AUTOSAR XML (schema 00046)
package /ComponentTypes
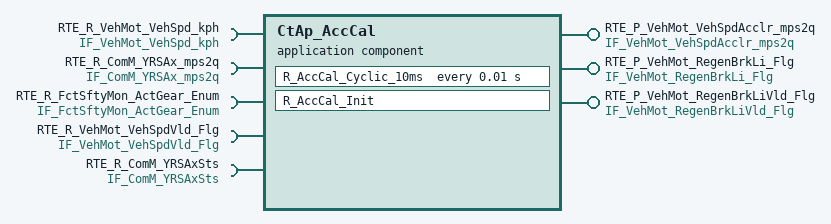
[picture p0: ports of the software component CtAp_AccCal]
  application sw component type CtAp_AccCal
    provide port RTE_P_VehMot_VehSpdAcclr_mps2q: nonqueued-sender-com-spec{data-element=tec_VehMot_VehSpdAcclr_mps2q, init-value=0}, provided-interface=IF_VehMot_VehSpdAcclr_mps2q
    provide port RTE_P_VehMot_RegenBrkLi_Flg: nonqueued-sender-com-spec{data-element=tec_VehMot_RegenBrkLi_Flg, init-value=0}, provided-interface=IF_VehMot_RegenBrkLi_Flg
    require port RTE_R_VehMot_VehSpd_kph: nonqueued-receiver-com-spec{data-element=tec_VehMot_VehSpd_kph, filter=data-filter-type=ALWAYS, init-value=0}, required-interface=IF_VehMot_VehSpd_kph
    require port RTE_R_ComM_YRSAx_mps2q: nonqueued-receiver-com-spec{data-element=tec_ComM_YRSAx_mps2q, filter=data-filter-type=ALWAYS, init-value=0}, required-interface=IF_ComM_YRSAx_mps2q
    provide port RTE_P_VehMot_RegenBrkLiVld_Flg: nonqueued-sender-com-spec{data-element=tec_VehMot_RegenBrkLiVld_Flg, init-value=0}, provided-interface=IF_VehMot_RegenBrkLiVld_Flg
    require port RTE_R_FctSftyMon_ActGear_Enum: nonqueued-receiver-com-spec{data-element=tec_FctSftyMon_ActGear_Enum, filter=data-filter-type=ALWAYS, init-value=0}, required-interface=IF_FctSftyMon_ActGear_Enum
    require port RTE_R_VehMot_VehSpdVld_Flg: nonqueued-receiver-com-spec{data-element=tec_VehMot_VehSpdVld_Flg, filter=data-filter-type=ALWAYS, init-value=0}, required-interface=IF_VehMot_VehSpdVld_Flg
    require port RTE_R_ComM_YRSAxSts: nonqueued-receiver-com-spec{data-element=tec_ComM_YRSAxSts, filter=data-filter-type=ALWAYS, init-value=0}, required-interface=IF_ComM_YRSAxSts
    behavior CtAp_AccCal_InternalBehavior
      timing event TMT_R_AccCal_Cyclic_10ms: start-on-event=R_AccCal_Cyclic_10ms, period=0.01
      init event CtAp_AccCal_InitEvent: start-on-event=R_AccCal_Init
      runnable R_AccCal_Cyclic_10ms
        data-receive-point-by-arguments:
          5 x access:
            REC_RTE_R_ComM_YRSAx_mps2q_tec_ComM_YRSAx_mps2q: accessed-variable=RTE_R_ComM_YRSAx_mps2q.tec_ComM_YRSAx_mps2q
            REC_RTE_R_VehMot_VehSpd_kph_tec_VehMot_VehSpd_kph: accessed-variable=RTE_R_VehMot_VehSpd_kph.tec_VehMot_VehSpd_kph
            REC_RTE_R_FctSftyMon_ActGear_Enum_tec_FctSftyMon_ActGear_Enum: accessed-variable=RTE_R_FctSftyMon_ActGear_Enum.tec_FctSftyMon_ActGear_Enum
            REC_RTE_R_VehMot_VehSpdVld_Flg_tec_VehMot_VehSpdVld_Flg: accessed-variable=RTE_R_VehMot_VehSpdVld_Flg.tec_VehMot_VehSpdVld_Flg
            REC_RTE_R_ComM_YRSAxSts_tec_ComM_YRSAxSts: accessed-variable=RTE_R_ComM_YRSAxSts.tec_ComM_YRSAxSts
        data-send-points:
          access SEND_RTE_P_VehMot_RegenBrkLiVld_Flg_tec_VehMot_RegenBrkLiVld_Flg: accessed-variable=RTE_P_VehMot_RegenBrkLiVld_Flg.tec_VehMot_RegenBrkLiVld_Flg
          access SEND_RTE_P_VehMot_RegenBrkLi_Flg_tec_VehMot_RegenBrkLi_Flg: accessed-variable=RTE_P_VehMot_RegenBrkLi_Flg.tec_VehMot_RegenBrkLi_Flg
          access SEND_RTE_P_VehMot_VehSpdAcclr_mps2q_tec_VehMot_VehSpdAcclr_mps2q: accessed-variable=RTE_P_VehMot_VehSpdAcclr_mps2q.tec_VehMot_VehSpdAcclr_mps2q
      runnable R_AccCal_Init
  swc implementation CtAp_AccCal_Implementation: behavior=CtAp_AccCal_InternalBehavior
